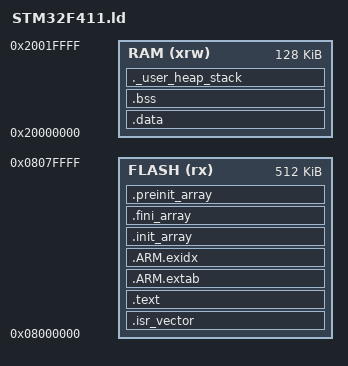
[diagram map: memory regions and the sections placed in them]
/* Minimal STM32F411 linker script placeholder */
ENTRY(Reset_Handler)

_estack = ORIGIN(RAM) + LENGTH(RAM);
_Min_Heap_Size = 0x200;
_Min_Stack_Size = 0x400;

MEMORY
{
    FLASH (rx) : ORIGIN = 0x08000000, LENGTH = 512K
    RAM (xrw)  : ORIGIN = 0x20000000, LENGTH = 128K
}

SECTIONS
{
    .isr_vector :
    {
        . = ALIGN(4);
        KEEP(*(.isr_vector))
        . = ALIGN(4);
    } > FLASH

    .text :
    {
        . = ALIGN(4);
        *(.text)
        *(.text.*)
        *(.glue_7)
        *(.glue_7t)
        *(.rodata)
        *(.rodata.*)
        . = ALIGN(4);
    } > FLASH

    .ARM.extab :
    {
        . = ALIGN(4);
        *(.ARM.extab* .gnu.linkonce.armextab.*)
        . = ALIGN(4);
    } > FLASH

    .ARM.exidx :
    {
        . = ALIGN(4);
        PROVIDE_HIDDEN(__exidx_start = .);
        *(.ARM.exidx* .gnu.linkonce.armexidx.*)
        . = ALIGN(4);
        PROVIDE_HIDDEN(__exidx_end = .);
    } > FLASH

    .init_array :
    {
        PROVIDE_HIDDEN(__init_array_start = .);
        KEEP(*(SORT(.init_array.*)))
        KEEP(*(.init_array))
        PROVIDE_HIDDEN(__init_array_end = .);
    } > FLASH

    .fini_array :
    {
        PROVIDE_HIDDEN(__fini_array_start = .);
        KEEP(*(SORT(.fini_array.*)))
        KEEP(*(.fini_array))
        PROVIDE_HIDDEN(__fini_array_end = .);
    } > FLASH

    .preinit_array :
    {
        PROVIDE_HIDDEN(__preinit_array_start = .);
        KEEP(*(.preinit_array))
        PROVIDE_HIDDEN(__preinit_array_end = .);
    } > FLASH

    _sidata = LOADADDR(.data);

    .data : AT (_sidata)
    {
        . = ALIGN(4);
        _sdata = .;
        *(.data)
        *(.data.*)
        . = ALIGN(4);
        _edata = .;
    } > RAM

    .bss (NOLOAD) :
    {
        . = ALIGN(4);
        _sbss = .;
        *(.bss)
        *(.bss.*)
        *(COMMON)
        . = ALIGN(4);
        _ebss = .;
        PROVIDE(end = .);
        PROVIDE(__end__ = .);
    } > RAM

    ._user_heap_stack (NOLOAD) :
    {
        . = ALIGN(8);
        PROVIDE(__heap_start__ = .);
        . = . + _Min_Heap_Size;
        . = ALIGN(8);
        PROVIDE(__HeapLimit = .);
        . = . + _Min_Stack_Size;
        . = ALIGN(8);
    } > RAM

    /DISCARD/ :
    {
        *(.comment)
        *(.note*)
    }
}
